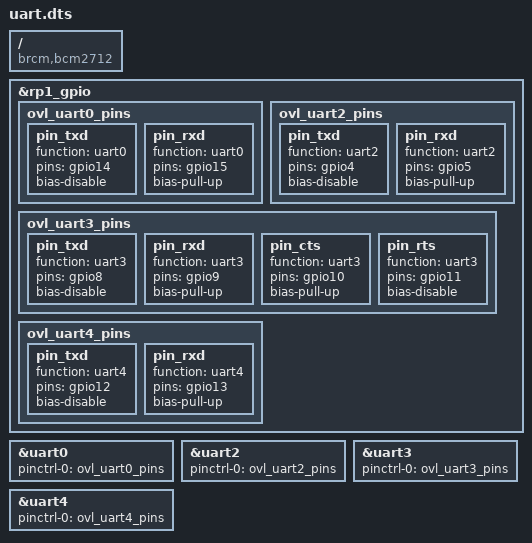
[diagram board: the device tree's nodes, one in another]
/dts-v1/;
/plugin/;

/{
  compatible = "brcm,bcm2712";

  /* CM5 overlay: 4x UART
  *
  * UART0: TXD=GPIO14, RXD=GPIO15                        (HAT pins 8/10)
  * UART2: TXD=GPIO4,  RXD=GPIO5                         (HAT pins 7/11)
  * UART3: TXD=GPIO8,  RXD=GPIO9, CTS=GPIO10, RTS=GPIO11 (HAT pins 24/21/19/23)
  * UART4: TXD=GPIO12, RXD=GPIO13                        (HAT pins 32/33)
  */

  fragment@0 {
    target = <&rp1_gpio>;
    __overlay__ {
      ovl_uart0_pins: ovl_uart0_pins {
        pin_txd {
          function = "uart0";
          pins = "gpio14";
          bias-disable;
        };
        pin_rxd {
          function = "uart0";
          pins = "gpio15";
          bias-pull-up;
        };
      };
      ovl_uart2_pins: ovl_uart2_pins {
        pin_txd {
          function = "uart2";
          pins = "gpio4";
          bias-disable;
        };
        pin_rxd {
          function = "uart2";
          pins = "gpio5";
          bias-pull-up;
        };
      };
      ovl_uart3_pins: ovl_uart3_pins {
        pin_txd {
          function = "uart3";
          pins = "gpio8";
          bias-disable;
        };
        pin_rxd {
          function = "uart3";
          pins = "gpio9";
          bias-pull-up;
        };
        pin_cts {
          function = "uart3";
          pins = "gpio10";
          bias-pull-up;
        };
        pin_rts {
          function = "uart3";
          pins = "gpio11";
          bias-disable;
        };
      };
      ovl_uart4_pins: ovl_uart4_pins {
        pin_txd {
          function = "uart4";
          pins = "gpio12";
          bias-disable;
        };
        pin_rxd {
          function = "uart4";
          pins = "gpio13";
          bias-pull-up;
        };
      };
    };
  };
  fragment@1 {
    target = <&uart0>;
    __overlay__ {
      status = "okay";
      pinctrl-0 = <&ovl_uart0_pins>;
    };
  };
  fragment@2 {
    target = <&uart2>;
    __overlay__ {
      status = "okay";
      pinctrl-0 = <&ovl_uart2_pins>;
    };
  };
  fragment@3 {
    target = <&uart3>;
    __overlay__ {
      status = "okay";
      pinctrl-0 = <&ovl_uart3_pins>;
    };
  };
  fragment@4 {
    target = <&uart4>;
    __overlay__ {
      status = "okay";
      pinctrl-0 = <&ovl_uart4_pins>;
    };
  };
};
